# STM32F417xx register map
File version: 1.0
Registers are 32-bit, read-write, reset 0x0 unless marked. A register's access mark holds for its fields unless they carry their own. Offsets are from the block's base; [hi:lo] are bit positions; {n}, {i} and the like mark numbered series; 'fields as' and 'values as' point back to an identical list.

## DCMI
Base 0x50050000
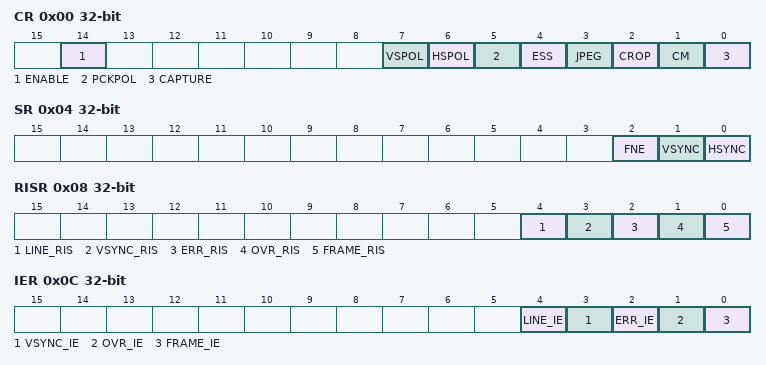
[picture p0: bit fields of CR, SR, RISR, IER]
0x00 CR — DCMI control register 1
  [14] ENABLE, [7] VSPOL, [6] HSPOL, [5] PCKPOL, [4] ESS, [3] JPEG, [2] CROP, [1] CM, [0] CAPTURE
0x04 SR — DCMI status register
  [2] FNE, [1] VSYNC, [0] HSYNC
0x08 RISR — DCMI raw interrupt status register
  [4] LINE_RIS, [3] VSYNC_RIS, [2] ERR_RIS, [1] OVR_RIS, [0] FRAME_RIS
0x0C IER — DCMI interrupt enable register
  [4] LINE_IE, [3] VSYNC_IE, [2] ERR_IE, [1] OVR_IE, [0] FRAME_IE
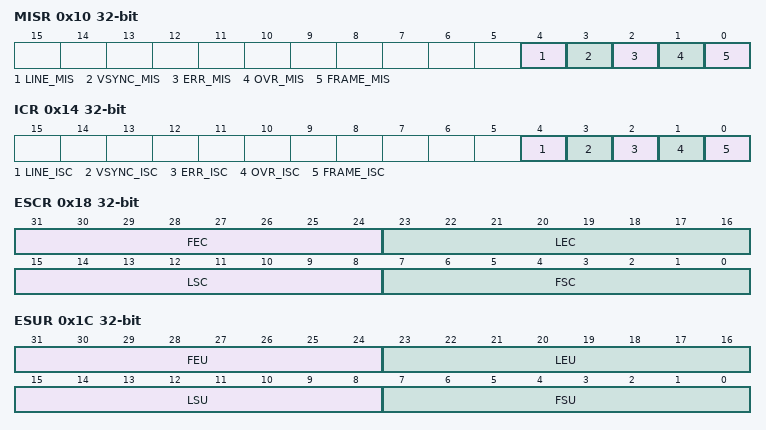
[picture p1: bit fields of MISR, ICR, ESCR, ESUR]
0x10 MISR — DCMI masked interrupt status register
  [4] LINE_MIS, [3] VSYNC_MIS, [2] ERR_MIS, [1] OVR_MIS, [0] FRAME_MIS
0x14 ICR — DCMI interrupt clear register
  [4] LINE_ISC, [3] VSYNC_ISC, [2] ERR_ISC, [1] OVR_ISC, [0] FRAME_ISC
0x18 ESCR — DCMI embedded synchronization code register
  [31:24] FEC, [23:16] LEC, [15:8] LSC, [7:0] FSC
0x1C ESUR — DCMI embedded synchronization unmask register
  [31:24] FEU, [23:16] LEU, [15:8] LSU, [7:0] FSU
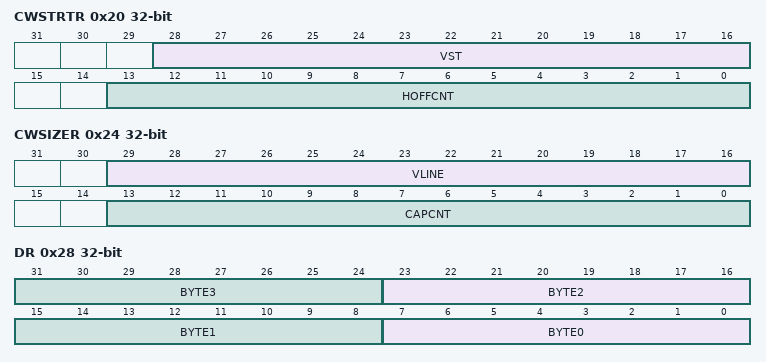
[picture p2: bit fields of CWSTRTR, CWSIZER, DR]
0x20 CWSTRTR — DCMI crop window start
  [28:16] VST, [13:0] HOFFCNT
0x24 CWSIZER — DCMI crop window size
  [29:16] VLINE, [13:0] CAPCNT
0x28 DR — DCMI data register
  [8n+7:8n] BYTE{n} (n=0..3)

## CRYP — Crypto Processor
Base 0x50060000
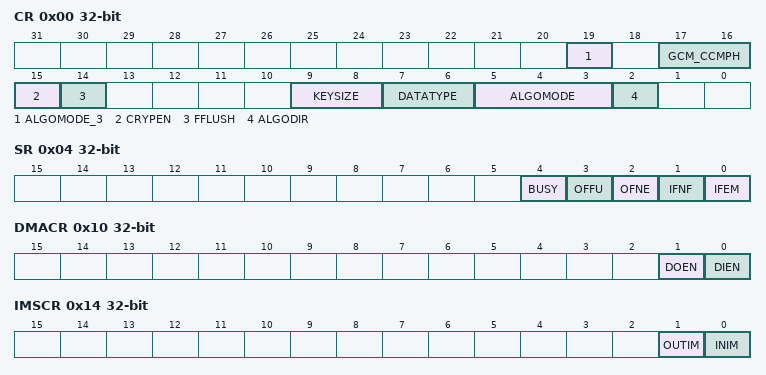
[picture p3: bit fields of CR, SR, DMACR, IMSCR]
0x00 CR — CRYP control register
  [19] ALGOMODE_3, [17:16] GCM_CCMPH, [15] CRYPEN, [14] FFLUSH, [9:8] KEYSIZE, [7:6] DATATYPE, [5:3] ALGOMODE, [2] ALGODIR
0x04 SR — CRYP status register
  [4] BUSY, [3] OFFU, [2] OFNE, [1] IFNF, [0] IFEM
0x08 DIN — CRYP data input register
0x0C DOUT — CRYP data output register
0x10 DMACR — CRYP DMA control register
  [1] DOEN, [0] DIEN
0x14 IMSCR — CRYP interrupt mask set/clear register
  [1] OUTIM, [0] INIM
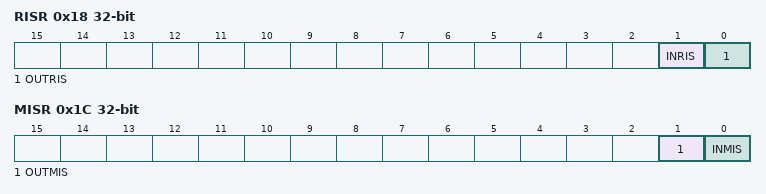
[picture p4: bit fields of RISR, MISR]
0x18 RISR — CRYP raw interrupt status register
  [1] INRIS, [0] OUTRIS
0x1C MISR — CRYP masked interrupt status register
  [1] OUTMIS, [0] INMIS
{0x20+8i} K{i}LR (i=0..3) — CRYP key left register {i}
{0x24+8i} K{i}RR (i=0..3) — CRYP key right register {i}
0x40 IV0LR — CRYP initialization vector left-word register 0
0x44 IV0RR — CRYP initialization vector right-word register 0
0x48 IV1LR — CRYP initialization vector left-word register 1
0x4C IV1RR — CRYP initialization vector right-word register 1
{0x50+4i} CSGCMCCM{i}R (i=0..7) — CRYP GCM/GMAC or CCM/CMAC context swap register {i}
{0x70+4i} CSGCM{i}R (i=0..7) — CRYP GCM/GMAC context swap register {i}

## HASH
Base 0x50060400
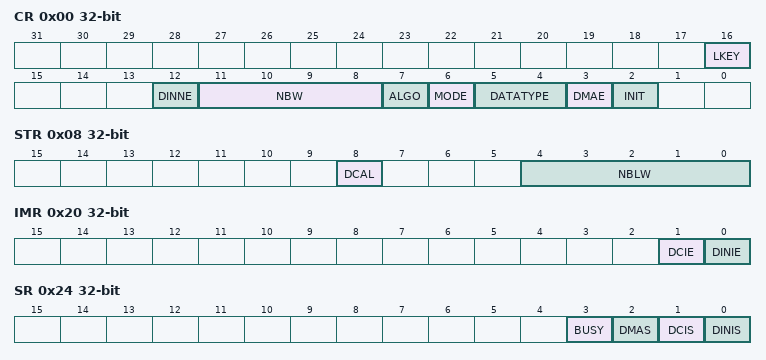
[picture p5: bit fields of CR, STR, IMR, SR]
0x00 CR — HASH control register
  [16] LKEY, [12] DINNE, [11:8] NBW, [7] ALGO, [6] MODE, [5:4] DATATYPE, [3] DMAE, [2] INIT
0x04 DIN — HASH data input register
0x08 STR — HASH start register
  [8] DCAL, [4:0] NBLW
{0xC+4i} HR{i} (i=0..4) — HASH digest registers
0x20 IMR — HASH interrupt enable register
  [1] DCIE, [0] DINIE
0x24 SR — HASH status register
  [3] BUSY, [2] DMAS, [1] DCIS, [0] DINIS
{0xF8+4i} CSR{i} (i=0..53) — HASH context swap registers
{0x310+4i} DIGEST_HR{i} (i=0..4) — HASH digest registers

## RNG
Base 0x50060800
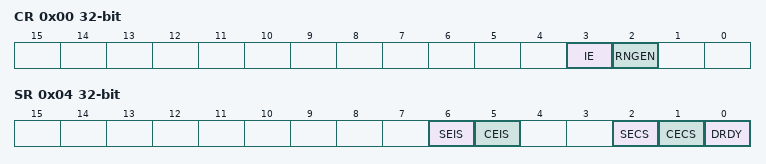
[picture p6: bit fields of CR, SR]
0x00 CR — RNG control register
  [3] IE, [2] RNGEN
0x04 SR — RNG status register
  [6] SEIS, [5] CEIS, [2] SECS, [1] CECS, [0] DRDY
0x08 DR — RNG data register

## FSMC
Base 0xA0000000
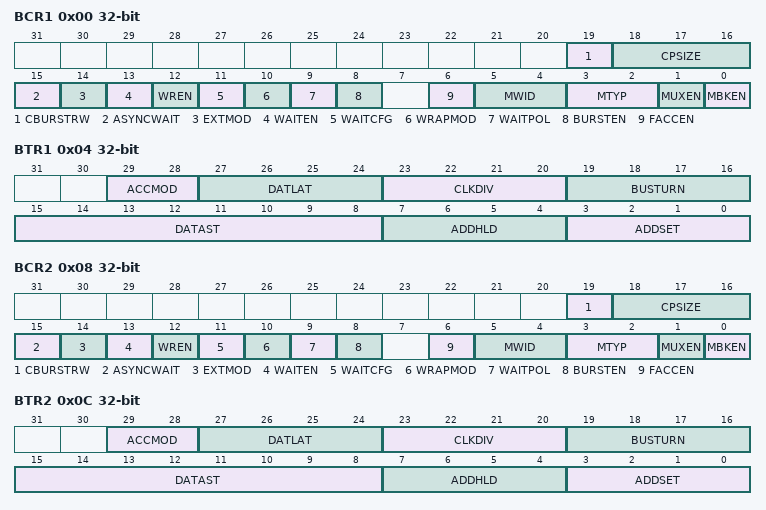
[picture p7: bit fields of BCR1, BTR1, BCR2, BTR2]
0x00 BCR1 — NOR/PSRAM chip-select control register(BCR) and chip-select timing register(BTR)
  [19] CBURSTRW — Write burst enable
  [18:16] CPSIZE — CRAM page size
  [15] ASYNCWAIT — Asynchronous wait
  [14] EXTMOD — Extended mode enable
  [13] WAITEN — Wait enable bit
  [12] WREN — Write enable bit
  [11] WAITCFG — Wait timing configuration
  [10] WRAPMOD — Wrapped burst mode support
  [9] WAITPOL — Wait signal polarity bit
  [8] BURSTEN — Burst enable bit
  [6] FACCEN — Flash access enable
  [5:4] MWID — MWID[1:0] bits (Memory data bus width)
  [3:2] MTYP — MTYP[1:0] bits (Memory type)
  [1] MUXEN — Address/data multiplexing enable bit
  [0] MBKEN — Memory bank enable bit
0x04 BTR1 — NOR/PSRAM chip-select control register(BCR) and chip-select timing register(BTR)
  [29:28] ACCMOD — ACCMOD[1:0] bits (Access mode)
  [27:24] DATLAT — DATLA[3:0] bits (Data latency)
  [23:20] CLKDIV — CLKDIV[3:0] bits (Clock divide ratio)
  [19:16] BUSTURN — BUSTURN[3:0] bits (Bus turnaround phase duration)
  [15:8] DATAST — DATAST [7:0] bits (Data-phase duration)
  [7:4] ADDHLD — ADDHLD[3:0] bits (Address-hold phase duration)
  [3:0] ADDSET — ADDSET[3:0] bits (Address setup phase duration)
0x08 BCR2 — NOR/PSRAM chip-select control register(BCR) and chip-select timing register(BTR)
  fields as BCR1
0x0C BTR2 — NOR/PSRAM chip-select control register(BCR) and chip-select timing register(BTR)
  fields as BTR1
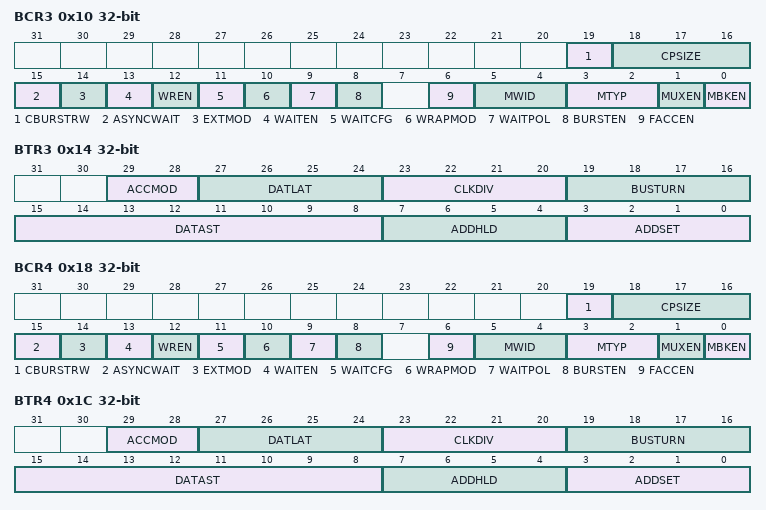
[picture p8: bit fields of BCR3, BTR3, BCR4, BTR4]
0x10 BCR3 — NOR/PSRAM chip-select control register(BCR) and chip-select timing register(BTR)
  fields as BCR1
0x14 BTR3 — NOR/PSRAM chip-select control register(BCR) and chip-select timing register(BTR)
  fields as BTR1
0x18 BCR4 — NOR/PSRAM chip-select control register(BCR) and chip-select timing register(BTR)
  fields as BCR1
0x1C BTR4 — NOR/PSRAM chip-select control register(BCR) and chip-select timing register(BTR)
  fields as BTR1
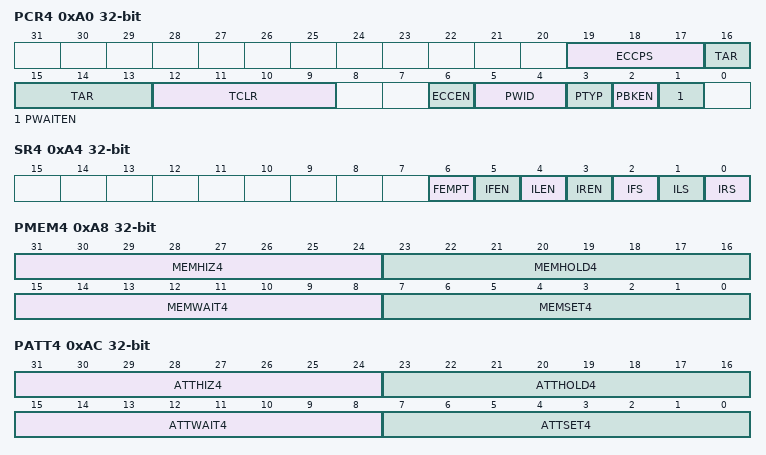
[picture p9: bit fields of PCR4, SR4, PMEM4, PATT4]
0xA0 PCR4 — PC Card control register 4
  [19:17] ECCPS — ECCPS[2:0] bits (ECC page size)
  [16:13] TAR — TAR[3:0] bits (ALE to RE delay)
  [12:9] TCLR — TCLR[3:0] bits (CLE to RE delay)
  [6] ECCEN — ECC computation logic enable bit
  [5:4] PWID — PWID[1:0] bits (NAND Flash databus width)
  [3] PTYP — Memory type
  [2] PBKEN — PC Card/NAND Flash memory bank enable bit
  [1] PWAITEN — Wait feature enable bit
0xA4 SR4 — PC Card FIFO status and interrupt register 4
  [6] FEMPT — FIFO empty
  [5] IFEN — Interrupt Falling Edge detection Enable bit
  [4] ILEN — Interrupt Level detection Enable bit
  [3] IREN — Interrupt Rising Edge detection Enable bit
  [2] IFS — Interrupt Falling Edge status
  [1] ILS — Interrupt Level status
  [0] IRS — Interrupt Rising Edge status
0xA8 PMEM4 — PC Card Common memory space timing register 4
  [31:24] MEMHIZ4 — MEMHIZ4[7:0] bits (Common memory 4 databus HiZ time)
  [23:16] MEMHOLD4 — MEMHOLD4[7:0] bits (Common memory 4 hold time)
  [15:8] MEMWAIT4 — MEMWAIT4[7:0] bits (Common memory 4 wait time)
  [7:0] MEMSET4 — MEMSET4[7:0] bits (Common memory 4 setup time)
0xAC PATT4 — PC Card Attribute memory space timing register 4
  [31:24] ATTHIZ4 — ATTHIZ4[7:0] bits (Attribute memory 4 databus HiZ time)
  [23:16] ATTHOLD4 — ATTHOLD4[7:0] bits (Attribute memory 4 hold time)
  [15:8] ATTWAIT4 — ATTWAIT4[7:0] bits (Attribute memory 4 wait time)
  [7:0] ATTSET4 — ATTSET4[7:0] bits (Attribute memory 4 setup time)
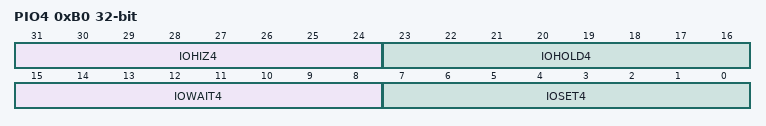
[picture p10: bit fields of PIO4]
0xB0 PIO4 — PC Card I/O space timing register 4
  [31:24] IOHIZ4 — IOHIZ4[7:0] bits (I/O 4 databus HiZ time)
  [23:16] IOHOLD4 — IOHOLD4[7:0] bits (I/O 4 hold time)
  [15:8] IOWAIT4 — IOWAIT4[7:0] bits (I/O 4 wait time)
  [7:0] IOSET4 — IOSET4[7:0] bits (I/O 4 setup time)
